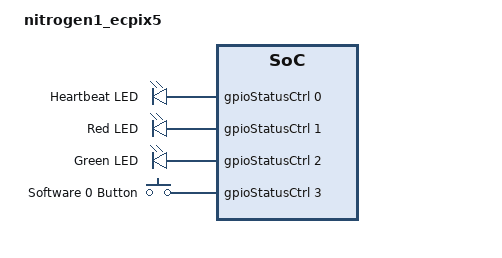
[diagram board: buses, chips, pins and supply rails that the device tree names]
/dts-v1/;
#include <elements/nitrogen1.dtsi>

/ {
	model = "nitrogen1_ecpix5";
	compatible = "elements,nitrogen1_ecpix5";

	memory {
		hyperram0: memory@90000000 {
			device_type = "memory";
			compatible = "zephyr,memory-region", "mmio-sram";
			reg = <0x90000000 DT_SIZE_M(8)>;
			zephyr,memory-region = "HYPERRAM0";
		};
	};

	aliases {
		sram-ext = &hyperram0;
	};

	chosen {
		zephyr,console = &uartStdCtrl;
		zephyr,shell-uart = &uartStdCtrl;
		zephyr,sram = &hyperram0;
	};

	leds {
		compatible = "gpio-leds";
		heartbeat: HEARTBEAT {
			gpios = <&gpioStatusCtrl 0 GPIO_ACTIVE_HIGH>;
			label = "Heartbeat LED";
		};

		red: RED {
			gpios = <&gpioStatusCtrl 1 GPIO_ACTIVE_HIGH>;
			label = "Red LED";
		};

		green: GREEN {
			gpios = <&gpioStatusCtrl 2 GPIO_ACTIVE_HIGH>;
			label = "Green LED";
		};
	};

	keys {
		compatible = "gpio-keys";
		sw0: SW0 {
			gpios = <&gpioStatusCtrl 3 GPIO_ACTIVE_HIGH>;
			label = "Software 0 Button";
		};
	};
};

&flash0 {
	reg = <0xa0000000 DT_SIZE_M(8)>;
};

&uartStdCtrl {
	clock-frequency = <100000000>;
};
